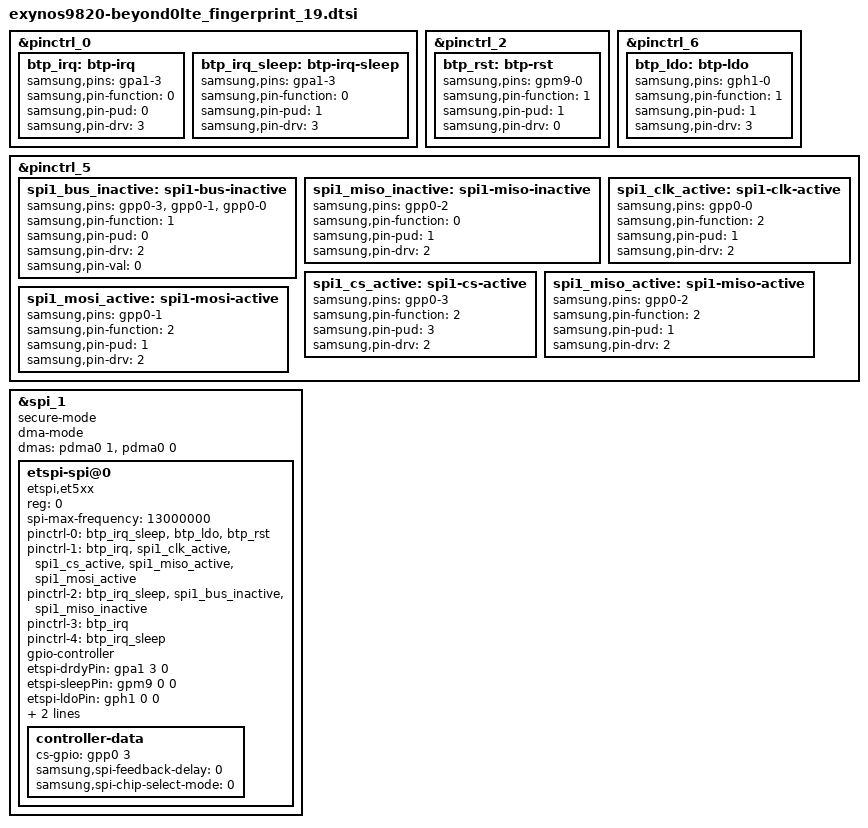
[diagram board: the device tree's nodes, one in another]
/*
 * Copyright (c) 2012-2013, The Linux Foundation. All rights reserved.
 *
 * This program is free software; you can redistribute it and/or modify
 * it under the terms of the GNU General Public License version 2 and
 * only version 2 as published by the Free Software Foundation.
 *
 * This program is distributed in the hope that it will be useful,
 * but WITHOUT ANY WARRANTY; without even the implied warranty of
 * MERCHANTABILITY or FITNESS FOR A PARTICULAR PURPOSE.  See the
 * GNU General Public License for more details.
 */

&pinctrl_0 {
	btp_irq: btp-irq {
		samsung,pins = "gpa1-3";
		samsung,pin-function = <0>;
		samsung,pin-pud = <0>;
		samsung,pin-drv = <3>;
	};
	btp_irq_sleep: btp-irq-sleep {
		samsung,pins = "gpa1-3";
		samsung,pin-function = <0>;
		samsung,pin-pud = <1>;
		samsung,pin-drv = <3>;
	};
};

&pinctrl_2 {
		btp_rst: btp-rst {
			samsung,pins = "gpm9-0";
			samsung,pin-function = <1>;
			samsung,pin-pud = <1>;
			samsung,pin-drv = <0>;
		};
};

&pinctrl_6 {
	btp_ldo: btp-ldo {
		samsung,pins = "gph1-0";
		samsung,pin-function = <1>;
		samsung,pin-pud = <1>;
		samsung,pin-drv = <3>;
	};
};

&pinctrl_5 {
	/* SPI_FP */
	spi1_bus_inactive: spi1-bus-inactive {
		samsung,pins = "gpp0-3", "gpp0-1", "gpp0-0";
		samsung,pin-function = <1>;
		samsung,pin-pud = <0>;
		samsung,pin-drv = <2>;
		samsung,pin-val = <0>;
	};
	spi1_miso_inactive: spi1-miso-inactive {
		samsung,pins = "gpp0-2";
		samsung,pin-function = <0>;
		samsung,pin-pud = <1>;
		samsung,pin-drv = <2>;
	};
	spi1_clk_active: spi1-clk-active {
		samsung,pins = "gpp0-0";
		samsung,pin-function = <2>;
		samsung,pin-pud = <1>;
		samsung,pin-drv = <2>;
	};
	spi1_cs_active: spi1-cs-active {
		samsung,pins = "gpp0-3";
		samsung,pin-function = <2>;
		samsung,pin-pud = <3>;
		samsung,pin-drv = <2>;
	};
	spi1_miso_active: spi1-miso-active {
		samsung,pins = "gpp0-2";
		samsung,pin-function = <2>;
		samsung,pin-pud = <1>;
		samsung,pin-drv = <2>;
	};
	spi1_mosi_active: spi1-mosi-active {
		samsung,pins = "gpp0-1";
		samsung,pin-function = <2>;
		samsung,pin-pud = <1>;
		samsung,pin-drv = <2>;
	};
};

/* SPI USI_PERIC0_USI00_SPI */
&spi_1 {
	status = "okay";
	secure-mode;
	/delete-property/ swap-mode;
	#address-cells = <1>;
	#size-cells = <0>;

	/delete-property/ pinctrl-names;
	/delete-property/ pinctrl-0;

	dma-mode;
	dmas = <&pdma0 1 &pdma0 0>;

	etspi-spi@0 {
		compatible = "etspi,et5xx";
		reg = <0>;
		spi-max-frequency = <13000000>;
		pinctrl-names = "default", "pins_poweron", "pins_poweroff"
						, "pins_poweron_tz", "pins_poweroff_tz";
		pinctrl-0 = <&btp_irq_sleep &btp_ldo &btp_rst>;
		pinctrl-1 = <&btp_irq &spi1_clk_active &spi1_cs_active &spi1_miso_active &spi1_mosi_active>;
		pinctrl-2 = <&btp_irq_sleep &spi1_bus_inactive &spi1_miso_inactive>;
		pinctrl-3 = <&btp_irq>;
		pinctrl-4 = <&btp_irq_sleep>;

		gpio-controller;
		#gpio-cells = <2>;

		etspi-drdyPin = <&gpa1 3 0>;
		etspi-sleepPin = <&gpm9 0 0>;
		etspi-ldoPin = <&gph1 0 0>;
		etspi-chipid = "ET523";
		etspi-orient = <2>;

		controller-data {
			cs-gpio = <&gpp0 3 0>;
			samsung,spi-feedback-delay = <0>;
			samsung,spi-chip-select-mode = <0>;
		};
	};
};
